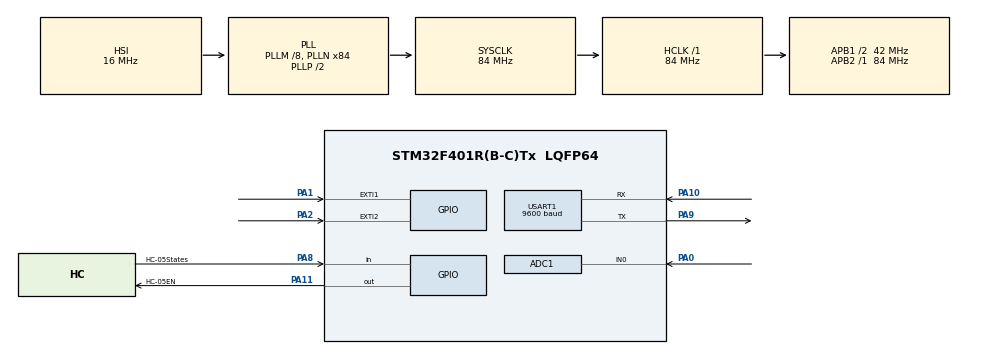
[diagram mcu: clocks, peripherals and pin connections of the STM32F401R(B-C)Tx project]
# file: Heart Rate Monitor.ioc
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ADC1.Channel-0\#ChannelRegularConversion=ADC_CHANNEL_0
ADC1.ClockPrescaler=ADC_CLOCK_SYNC_PCLK_DIV4
ADC1.ContinuousConvMode=ENABLE
ADC1.DMAContinuousRequests=ENABLE
ADC1.InjNumberOfConversion=0
ADC1.NbrOfConversion=1
ADC1.NbrOfConversionFlag=1
ADC1.Rank-0\#ChannelRegularConversion=1
ADC1.SamplingTime-0\#ChannelRegularConversion=ADC_SAMPLETIME_28CYCLES
ADC1.ScanConvMode=DISABLE
ADC1.master=1
Dma.ADC1.0.Direction=DMA_PERIPH_TO_MEMORY
Dma.ADC1.0.FIFOMode=DMA_FIFOMODE_DISABLE
Dma.ADC1.0.Instance=DMA2_Stream4
Dma.ADC1.0.MemDataAlignment=DMA_MDATAALIGN_HALFWORD
Dma.ADC1.0.MemInc=DMA_MINC_ENABLE
Dma.ADC1.0.Mode=DMA_CIRCULAR
Dma.ADC1.0.PeriphDataAlignment=DMA_PDATAALIGN_HALFWORD
Dma.ADC1.0.PeriphInc=DMA_PINC_DISABLE
Dma.ADC1.0.Priority=DMA_PRIORITY_LOW
Dma.Request0=ADC1
Mcu.Family=STM32F4
Mcu.Name=STM32F401R(B-C)Tx
Mcu.Package=LQFP64
NVIC.DMA2_Stream4_IRQn=true\:0\:0\:false\:false\:true\:false\:true\:true
NVIC.PriorityGroup=NVIC_PRIORITYGROUP_4
PA0-WKUP.Signal=ADCx_IN0
PA1.GPIO_PuPd=GPIO_PULLUP
PA1.Signal=GPXTI1
PA10.Mode=Asynchronous
PA10.Signal=USART1_RX
PA11.GPIO_Label=HC-05EN
PA11.Signal=GPIO_Output
PA2.GPIO_PuPd=GPIO_PULLUP
PA2.Signal=GPXTI2
PA8.GPIO_Label=HC-05States
PA8.Signal=GPIO_Input
PA9.Mode=Asynchronous
PA9.Signal=USART1_TX
ProjectManager.HeapSize=0x200
ProjectManager.StackSize=0x400
ProjectManager.TargetToolchain=STM32CubeIDE
RCC.48MHZClocksFreq_Value=42000000
RCC.AHBFreq_Value=84000000
RCC.APB1CLKDivider=RCC_HCLK_DIV2
RCC.APB1Freq_Value=42000000
RCC.APB1TimFreq_Value=84000000
RCC.APB2Freq_Value=84000000
RCC.APB2TimFreq_Value=84000000
RCC.CortexFreq_Value=84000000
RCC.HCLKFreq_Value=84000000
RCC.HSE_VALUE=25000000
RCC.HSI_VALUE=16000000
RCC.LSE_VALUE=32768
RCC.PLLM=8
RCC.PLLN=84
RCC.SYSCLKFreq_VALUE=84000000
RCC.SYSCLKSource=RCC_SYSCLKSOURCE_PLLCLK
RCC.VCOOutputFreq_Value=168000000
SH.ADCx_IN0.0=ADC1_IN0,IN0
USART1.BaudRate=9600
USART1.VirtualMode=VM_ASYNC
board=custom

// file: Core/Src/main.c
/* USER CODE BEGIN Header */
/**
  ******************************************************************************
  * @file           : main.c
  * @brief          : Main program body
  ******************************************************************************
  * @attention
  *
  * Copyright (c) 2025 STMicroelectronics.
  * All rights reserved.
  *
  * This software is licensed under terms that can be found in the LICENSE file
  * in the root directory of this software component.
  * If no LICENSE file comes with this software, it is provided AS-IS.
  *
  ******************************************************************************
  */
/* USER CODE END Header */
#include "main.h"
#include "adc.h"
#include "dma.h"
#include "usart.h"
#include "gpio.h"
#include "FreeRTOS.h"
#include "task.h"
#include "time.h"
#include "queue.h"
#include "AD8232.h"
#include "HC-05.h"

/* USER CODE BEGIN PTD */
QueueHandle_t ecgQueue;
QueueHandle_t ecgQueueState;

/* USER CODE END PTD */
void GetECGRead(void*pr){
	uint16_t ECGValue=0;
	AD8232_Status_t State;
	while(1){
		ECGValue=AD8232_GetHeartRate();
		State=AD8232_CheckLeadOff();
		xQueueSend(ecgQueue, &ECGValue, portMAX_DELAY); // Send to queue
		vTaskDelay(pdMS_TO_TICKS(10)); // Sample every 10ms (adjustable)
		xQueueSend(ecgQueueState, &State, portMAX_DELAY); // Send to queue
		vTaskDelay(pdMS_TO_TICKS(10)); // Sample every 10ms (adjustable)
	}
}
void SendData(void*PR){
	uint16_t ECGValue=0;
	char str1[10];
	AD8232_Status_t State;
	char str2[10];
	while(1){
		if (xQueueReceive(ecgQueue, &ECGValue, portMAX_DELAY) == pdTRUE) {
			sprintf(str1, "%d\n", ECGValue); // Convert to string
			HC05_SendData((uint8_t *)str1, strlen(str1));
			}
		if (xQueueReceive(ecgQueue, &State, portMAX_DELAY) == pdTRUE) {
					sprintf(str2, "%d\n", State); // Convert to string
					HC05_SendData((uint8_t *)str2, strlen(str2));
			}
	}
}

void SystemClock_Config(void);

int main(void)
{

  /* MCU Configuration--------------------------------------------------------*/

  /* Reset of all peripherals, Initializes the Flash interface and the Systick. */
  HAL_Init();

  /* Configure the system clock */
  SystemClock_Config();

  /* Initialize all configured peripherals */
  MX_GPIO_Init();
  MX_DMA_Init();
  MX_ADC1_Init();
  MX_USART1_UART_Init();
  /* USER CODE BEGIN 2 */
  AD8232_Init(&hdma_adc1);
  HC05_Init(&huart1);
  /* USER CODE END 2 */
  ecgQueue = xQueueCreate(10, sizeof(uint16_t)); // Queue for ECG values
  ecgQueueState = xQueueCreate(10, sizeof(AD8232_Status_t)); // Queue for ECG values
  xTaskCreate(GetECGRead, "ECG Task", 128, NULL, 2, NULL);
  xTaskCreate(SendData, "BT Task", 128, NULL, 1, NULL);
  vTaskStartScheduler();

  /* Infinite loop */
  while (1)
  {

  }
}

void SystemClock_Config(void)
{
  RCC_OscInitTypeDef RCC_OscInitStruct = {0};
  RCC_ClkInitTypeDef RCC_ClkInitStruct = {0};

  /** Configure the main internal regulator output voltage
  */
  __HAL_RCC_PWR_CLK_ENABLE();
  __HAL_PWR_VOLTAGESCALING_CONFIG(PWR_REGULATOR_VOLTAGE_SCALE2);

  /** Initializes the RCC Oscillators according to the specified parameters
  * in the RCC_OscInitTypeDef structure.
  */
  RCC_OscInitStruct.OscillatorType = RCC_OSCILLATORTYPE_HSI;
  RCC_OscInitStruct.HSIState = RCC_HSI_ON;
  RCC_OscInitStruct.HSICalibrationValue = RCC_HSICALIBRATION_DEFAULT;
  RCC_OscInitStruct.PLL.PLLState = RCC_PLL_ON;
  RCC_OscInitStruct.PLL.PLLSource = RCC_PLLSOURCE_HSI;
  RCC_OscInitStruct.PLL.PLLM = 8;
  RCC_OscInitStruct.PLL.PLLN = 84;
  RCC_OscInitStruct.PLL.PLLP = RCC_PLLP_DIV2;
  RCC_OscInitStruct.PLL.PLLQ = 4;
  if (HAL_RCC_OscConfig(&RCC_OscInitStruct) != HAL_OK)
  {
    Error_Handler();
  }

  /** Initializes the CPU, AHB and APB buses clocks
  */
  RCC_ClkInitStruct.ClockType = RCC_CLOCKTYPE_HCLK|RCC_CLOCKTYPE_SYSCLK
                              |RCC_CLOCKTYPE_PCLK1|RCC_CLOCKTYPE_PCLK2;
  RCC_ClkInitStruct.SYSCLKSource = RCC_SYSCLKSOURCE_PLLCLK;
  RCC_ClkInitStruct.AHBCLKDivider = RCC_SYSCLK_DIV1;
  RCC_ClkInitStruct.APB1CLKDivider = RCC_HCLK_DIV2;
  RCC_ClkInitStruct.APB2CLKDivider = RCC_HCLK_DIV1;

  if (HAL_RCC_ClockConfig(&RCC_ClkInitStruct, FLASH_LATENCY_2) != HAL_OK)
  {
    Error_Handler();
  }
}

void Error_Handler(void)
{
  __disable_irq();
  while (1)
  {
  }
}
void vApplicationStackOverflowHook(TaskHandle_t xTask, char *pcTaskName)
{
    /* Handle stack overflow */

    /* You can add an LED indication or reset the system */
    while(1);  // Halt execution (optional)
}

void vApplicationMallocFailedHook(void)
{
    /* Handle stack overflow */

    /* You can add an LED indication or reset the system */
    while(1);  // Halt execution (optional)
}
